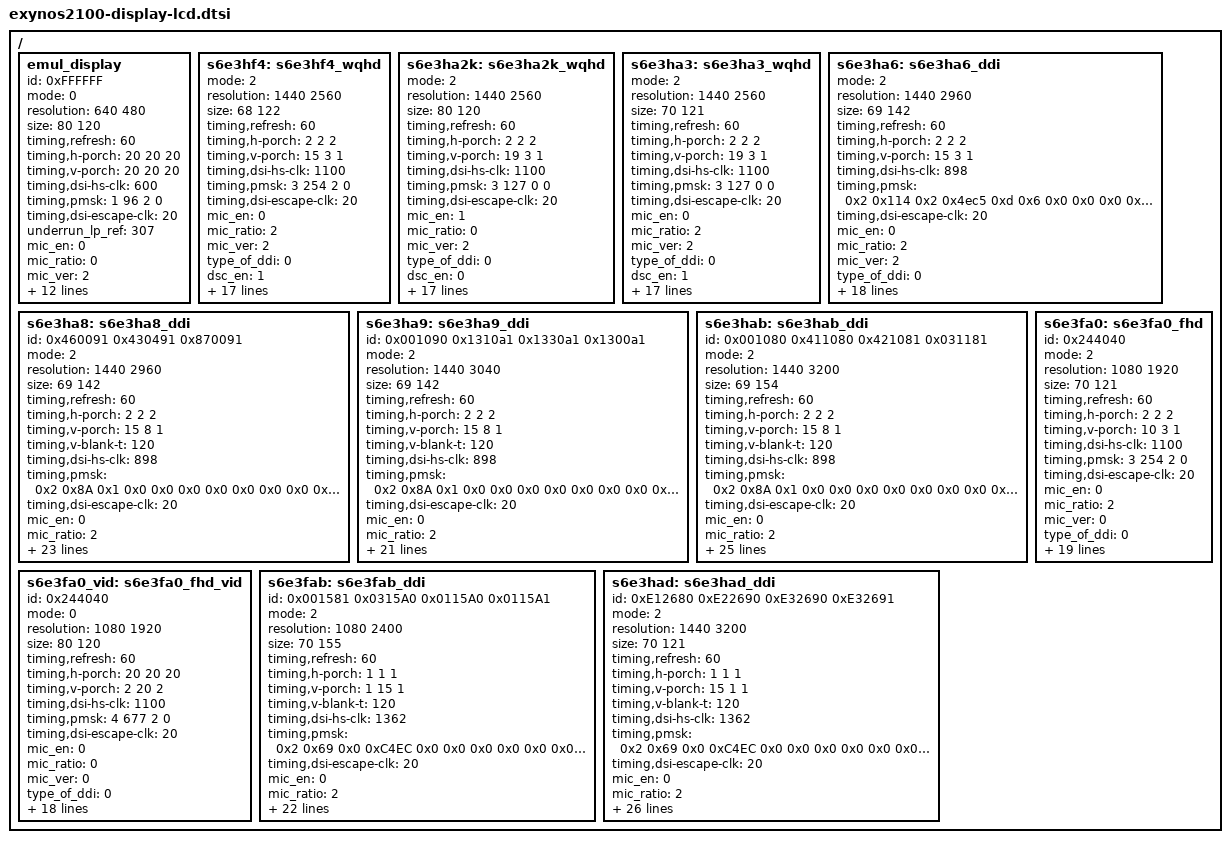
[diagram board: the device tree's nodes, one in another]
/*
 * SAMSUNG LCD Panel Device Tree Source
 *
 * Copyright (c) 2017 Samsung Electronics Co., Ltd.
 *		http://www.samsung.com
 *
 * This program is free software; you can redistribute it and/or modify
 * it under the terms of the GNU General Public License version 2 as
 * published by the Free Software Foundation.
 */

/ {
	fragment@lcd {
		target-path = "/";
		__overlay__ {
			emul_display: emul_display {
				id = <0xFFFFFF>;
				mode = <0>; /* 0: video mode, 1: DP command mode, 2: MIPI command mode */
				resolution = <640 480>;
		/*		resolution = <1080 1920>; */
				size = <80 120>;
				timing,refresh = <60>;
				timing,h-porch = <20 20 20>;
				timing,v-porch = <20 20 20>;
				timing,dsi-hs-clk = <600>;
				/* TODO : pmsk value to be set */
				timing,pmsk = <1 96 2 0>;
				timing,dsi-escape-clk = <20>;
				underrun_lp_ref = <307>;
				mic_en = <0>;			/* 0: Disable, 1: Enable */
				mic_ratio = <0>;		/* 0: 1/2 mic, 1: 1/3 mic */
				mic_ver = <2>;			/* 0: mic v1.1, 1: v1.2, 2: v2.0 */
				type_of_ddi = <0>;		/* 0: Samsung Mobile, 1: MAGNA, 2: Normal(Etc) */
				dsc_en = <0>;			/* 0: Disable, 1: Enable */
				dsc_cnt = <0>;			/* used DSC count */
				dsc_slice_num = <0>;		/* count of dsc slice */
				data_lane = <4>;		/* number of using data lane */
				cmd_underrun_lp_ref = <1203>;	/* for underrun detect at command mode*/
				vt_compensation = <10731>;	/* wclk = 100MHZ, 320 x 240 for underrun detect at video mode*/
				hdr_num = <0>;			/* max: 4 */
				hdr_type = <0 0 0 0>;		/* 1: DOLBY_VISION, 2: HDR10, 3: HLG */
				hdr_max_luma = <0>;		/* 0 */
				hdr_max_avg_luma = <0>;		/* 0 */
				hdr_min_luma = <0>;		/* 0.0000 */
			};

			s6e3hf4: s6e3hf4_wqhd {
				mode = <2>;			/* 0: video mode, 1: DP command mode, 2: MIPI command mode */
				resolution = <1440 2560>; 	/* <720 1280> - dsc disable, <1440 2560> - dsc enable */
				size = <68 122>;
				timing,refresh = <60>;
				timing,h-porch = <2 2 2>;
				timing,v-porch = <15 3 1>;
				timing,dsi-hs-clk = <1100>;	/* <600> - <3 277 3 0>, <898> - <2 138 2 0> */
				timing,pmsk = <3 254 2 0>;
				timing,dsi-escape-clk = <20>;
				mic_en = <0>;			/* 0: Disable, 1: Enable */
				mic_ratio = <2>;		/* 0: 1/2 mic, 1: 1/3 mic */
				mic_ver = <2>;			/* 0: mic v1.1, 1: v1.2, 2: v2.0 */
				type_of_ddi = <0>;		/* 0: Samsung Mobile, 1: MAGNA, 2: Normal(Etc) */
				dsc_en = <1>;			/* 0: Disable, 1: Enable */
				dsc_cnt = <2>;			/* used DSC count */
				dsc_slice_num = <4>;		/* count of dsc slice */
				dsc_slice_h = <64>;		/* height of dsc slice */
				data_lane = <4>;		/* number of using data lane */
				cmd_underrun_lp_ref = <5629>;	/* for underrun detect (max : 65535) */
				mres_en = <0>;
				mres_number = <1>;
				mres_width = <1440 0 0>;
				mres_height = <2560 0 0>;
				mres_dsc_width = <360 0 0>;
				mres_dsc_height = <64 0 0>;
				mres_dsc_en = <1 0 0>;
				hdr_num = <1>;			/* max: 4 */
				hdr_type = <2 0 0 0>;		/* 1: DOLBY_VISION, 2: HDR10, 3: HLG */
				hdr_max_luma = <5400000>;	/* 540 */
				hdr_max_avg_luma = <1200000>;	/* 120 */
				hdr_min_luma = <5>;		/* 0.0005 */
			};

			s6e3ha2k: s6e3ha2k_wqhd {
				mode = <2>;			/* 0: video mode, 1: DP command mode, 2: MIPI command mode */
				resolution = <1440 2560>;
				size = <80 120>;
				timing,refresh = <60>;
				timing,h-porch = <2 2 2>;
				timing,v-porch = <19 3 1>;
				timing,dsi-hs-clk = <1100>;
				timing,pmsk = <3 127 0 0>;
				timing,dsi-escape-clk = <20>;
				mic_en = <1>;			/* 0: Disable, 1: Enable */
				mic_ratio = <0>;		/* 0: 1/2 mic, 1: 1/3 mic */
				mic_ver = <2>;			/* 0: mic v1.1, 1: v1.2, 2: v2.0 */
				type_of_ddi = <0>;		/* 0: Samsung Mobile, 1: MAGNA, 2: Normal(Etc) */
				dsc_en = <0>;			/* 0: Disable, 1: Enable */
				dsc_cnt = <0>;			/* used DSC count */
				dsc_slice_num = <0>;		/* count of dsc slice */
				dsc_slice_h = <0>;		/* height of dsc slice */
				data_lane = <4>;		/* number of using data lane */
				cmd_underrun_lp_ref = <1203>;	/* for underrun detect*/
				mres_en = <0>;
				mres_number = <1>;
				mres_width = <1440 0 0>;
				mres_height = <2560 0 0>;
				mres_dsc_width = <0 0 0>;
				mres_dsc_height = <0 0 0>;
				mres_dsc_en = <0 0 0>;
				hdr_num = <1>;			/* max: 4 */
				hdr_type = <2 0 0 0>;		/* 1: DOLBY_VISION, 2: HDR10, 3: HLG */
				hdr_max_luma = <5400000>;	/* 540 */
				hdr_max_avg_luma = <1200000>;	/* 120 */
				hdr_min_luma = <5>;		/* 0.0005 */
			};

			s6e3ha3: s6e3ha3_wqhd {
				mode = <2>;			/* 0: video mode, 1: DP command mode, 2: MIPI command mode */
				resolution = <1440 2560>;
				size = <70 121>;
				timing,refresh = <60>;
				timing,h-porch = <2 2 2>;
				timing,v-porch = <19 3 1>;
				timing,dsi-hs-clk = <1100>;
				timing,pmsk = <3 127 0 0>;
				timing,dsi-escape-clk = <20>;
				mic_en = <0>;			/* 0: Disable, 1: Enable */
				mic_ratio = <2>;		/* 0: 1/2 mic, 1: 1/3 mic */
				mic_ver = <2>;			/* 0: mic v1.1, 1: v1.2, 2: v2.0 */
				type_of_ddi = <0>;		/* 0: Samsung Mobile, 1: MAGNA, 2: Normal(Etc) */
				dsc_en = <1>;			/* 0: Disable, 1: Enable */
				dsc_cnt = <1>;			/* used DSC count */
				dsc_slice_num = <1>;		/* count of dsc slice */
				dsc_slice_h = <32>;		/* height of dsc slice */
				data_lane = <4>;		/* number of using data lane */
				cmd_underrun_lp_ref = <1203>;	/* for underrun detect*/
				mres_en = <0>;
				mres_number = <1>;
				mres_width = <1440 0 0>;
				mres_height = <2560 0 0>;
				mres_dsc_width = <1440 0 0>;
				mres_dsc_height = <32 0 0>;
				mres_dsc_en = <1 0 0>;
				hdr_num = <1>;			/* max: 4 */
				hdr_type = <2 0 0 0>;		/* 1: DOLBY_VISION, 2: HDR10, 3: HLG */
				hdr_max_luma = <5400000>;	/* 540 */
				hdr_max_avg_luma = <1200000>;	/* 120 */
				hdr_min_luma = <5>;		/* 0.0005 */
			};

			s6e3ha6: s6e3ha6_ddi {
				mode = <2>;
				resolution = <1440 2960>;
				size = <69 142>;
				timing,refresh = <60>;
				timing,h-porch = <2 2 2>;
				timing,v-porch = <15 3 1>;
				timing,dsi-hs-clk = <898>;
				timing,pmsk = <
					0x2 0x114 0x2 0x4ec5 /* p m s k */
					0xd 0x6 0x0 0x0    /* mfr mrr sel_pf icp */
					0x0 0x0 0x0 0x0    /* afc_enb extafc feed_en fsel */
					0x0 0x0              /* fout_mask rsel */
					>;
				timing,dsi-escape-clk = <20>;
				mic_en = <0>;			/* 0: Disable, 1: Enable */
				mic_ratio = <2>;		/* 0: 1/2 mic, 1: 1/3 mic */
				mic_ver = <2>;			/* 0: mic v1.1, 1: v1.2, 2: v2.0 */
				type_of_ddi = <0>;		/* 0: Samsung Mobile, 1: MAGNA, 2: Normal(Etc) */
				dsc_en = <1>;			/* 0: Disable, 1: Enable */
				dsc_cnt = <2>;			/* used DSC count */
				dsc_slice_num = <2>;		/* count of dsc slice */
				dsc_slice_h = <40>;		/* height of dsc slice */
				data_lane = <4>;		/* number of using data lane */
				cmd_underrun_lp_ref = <3744 5359 4367>;	/* for underrun detect*/
				mres_en = <1>;
				mres_number = <3>;
				mres_width = <1440 1080 720>;
				mres_height = <2960 2220 1480>;
				mres_dsc_width = <720 540 360>;
				mres_dsc_height = <40 30 74>;
				mres_dsc_en = <1 1 0>;
				hdr_num = <1>;			/* max: 4 */
				hdr_type = <2 0 0 0>;		/* 1: DOLBY_VISION, 2: HDR10, 3: HLG */
				hdr_max_luma = <5400000>;	/* 540 */
				hdr_max_avg_luma = <1200000>;	/* 120 */
				hdr_min_luma = <5>;		/* 0.0005 */
			};


			s6e3ha8: s6e3ha8_ddi {
				id = <0x460091 0x430491 0x870091>;
				mode = <2>;
				resolution = <1440 2960>;
				size = <69 142>;
				timing,refresh = <60>;
				timing,h-porch = <2 2 2>;
				timing,v-porch = <15 8 1>;
				timing,v-blank-t = <120>;	/* (usec) command: TE pulse time, video: vbp+vfp time */
				timing,dsi-hs-clk = <898>;	/* <600> - <3 277 3 0>, <898> - <2 138 2 0> */
				timing,pmsk = <
					0x2 0x8A  0x1 0x0	/* p m s k */
					0x0 0x0	  0x0 0x0	/* mfr mrr sel_pf icp */
					0x0 0x0   0x0 0x0	/* afc_enb extafc feed_en fsel */
					0x0 0x0          	/* fout_mask rsel */
					>;
				timing,dsi-escape-clk = <20>;
				mic_en = <0>;			/* 0: Disable, 1: Enable */
				mic_ratio = <2>;		/* 0: 1/2 mic, 1: 1/3 mic */
				mic_ver = <2>;			/* 0: mic v1.1, 1: v1.2, 2: v2.0 */
				type_of_ddi = <0>;		/* 0: Samsung Mobile, 1: MAGNA, 2: Normal(Etc) */
				dsc_en = <1>;			/* 0: Disable, 1: Enable */
				dsc_cnt = <2>;			/* used DSC count */
				dsc_slice_num = <2>;		/* count of dsc slice */
				dsc_slice_h = <40>;		/* height of dsc slice */
				data_lane = <4>;		/* number of using data lane */
				mres_en = <1>;
				mres_number = <3>;
				mres_width = <1440 1080 720>;
				mres_height = <2960 2220 1480>;
				mres_dsc_width = <720 540 360>;
				mres_dsc_height = <40 30 74>;
				mres_dsc_en = <1 1 1>;
				default_mode = <0>;
				/* <xres : yres : fps : lp_ref : dsc_en : slice_w : slice_h> */
				display_mode = <1440 2960 60 3022 1 720 40>,
					       <1080 2220 60 5359 1 540 30>,
					       <720 1480 60 7031 1 360 74>;
				hdr_num = <1>;			/* max: 4 */
				hdr_type = <2 0 0 0>;		/* 1: DOLBY_VISION, 2: HDR10, 3: HLG */
				hdr_max_luma = <5400000>;	/* 540 */
				hdr_max_avg_luma = <1200000>;	/* 120 */
				hdr_min_luma = <5>;		/* 0.0005 */
			};

			s6e3ha9: s6e3ha9_ddi {
				id = <0x001090 0x1310a1 0x1330a1 0x1300a1>;
				mode = <2>;
				resolution = <1440 3040>;
				size = <69 142>;
				timing,refresh = <60>;
				timing,h-porch = <2 2 2>;
				timing,v-porch = <15 8 1>;
				timing,v-blank-t = <120>;	/* (usec) command: TE pulse time, video: vbp+vfp time */
				timing,dsi-hs-clk = <898>;	/* <600> - <3 277 3 0>, <898> - <2 138 2 0> */
				timing,pmsk = <
					0x2 0x8A  0x1 0x0    /* p m s k */
					0x0 0x0	  0x0 0x0    /* mfr mrr sel_pf icp */
					0x0 0x0   0x0 0x0    /* afc_enb extafc feed_en fsel */
					0x0 0x0              /* fout_mask rsel */
					>;
				timing,dsi-escape-clk = <20>;
				mic_en = <0>;			/* 0: Disable, 1: Enable */
				mic_ratio = <2>;		/* 0: 1/2 mic, 1: 1/3 mic */
				mic_ver = <2>;			/* 0: mic v1.1, 1: v1.2, 2: v2.0 */
				type_of_ddi = <0>;		/* 0: Samsung Mobile, 1: MAGNA, 2: Normal(Etc) */
				dsc_en = <1>;			/* 0: Disable, 1: Enable */
				dsc_cnt = <2>;			/* used DSC count */
				dsc_slice_num = <2>;		/* count of dsc slice */
				dsc_slice_h = <40>;		/* height of dsc slice */
				data_lane = <4>;		/* number of using data lane */
				mres_en = <0>;
				mres_number = <3>;
				mres_width = <1440 1080 720>;
				mres_height = <3040 2280 1520>;
				mres_dsc_width = <720 540 360>;
				mres_dsc_height = <40 30 74>;
				mres_dsc_en = <1 1 1>;
				default_mode = <0>;
				/* <xres : yres : fps : lp_ref : dsc_en : slice_w : slice_h> */
				display_mode = <1440 3040 60 2877 1 720 40>;
				hdr_num = <1>;			/* max: 4 */
				hdr_type = <2 0 0 0>;		/* 1: DOLBY_VISION, 2: HDR10, 3: HLG */
				hdr_max_luma = <5400000>;	/* 540 */
				hdr_max_avg_luma = <1200000>;	/* 120 */
				hdr_min_luma = <5>;		/* 0.0005 */
			};

			s6e3hab: s6e3hab_ddi {
				id = <0x001080 0x411080 0x421081 0x031181>;
				mode = <2>;
				resolution = <1440 3200>;
				size = <69 154>;
				timing,refresh = <60>;
				timing,h-porch = <2 2 2>;
				timing,v-porch = <15 8 1>;
				timing,v-blank-t = <120>;	/* (usec) command: TE pulse time, video: vbp+vfp time */
				timing,dsi-hs-clk = <898>;	/* <600> - <3 277 3 0>, <898> - <2 138 2 0> */
				timing,pmsk = <
					0x2 0x8A  0x1 0x0	/* p m s k */
					0x0 0x0	  0x0 0x0	/* mfr mrr sel_pf icp */
					0x0 0x0   0x0 0x0	/* afc_enb extafc feed_en fsel */
					0x0 0x0          	/* fout_mask rsel */
					>;
				timing,dsi-escape-clk = <20>;
				mic_en = <0>;			/* 0: Disable, 1: Enable */
				mic_ratio = <2>;		/* 0: 1/2 mic, 1: 1/3 mic */
				mic_ver = <2>;			/* 0: mic v1.1, 1: v1.2, 2: v2.0 */
				type_of_ddi = <0>;		/* 0: Samsung Mobile, 1: MAGNA, 2: Normal(Etc) */
				dsc_en = <1>;			/* 0: Disable, 1: Enable */
				dsc_cnt = <2>;			/* used DSC count */
				dsc_slice_num = <2>;		/* count of dsc slice */
				dsc_slice_h = <40>;		/* height of dsc slice */
				data_lane = <4>;		/* number of using data lane */
				mres_en = <1>;
				mres_number = <3>;
				mres_width = <1440 1080 720>;
				mres_height = <3200 2400 1600>;
				mres_dsc_width = <720 540 360>;
				mres_dsc_height = <40 40 80>;
				mres_dsc_en = <1 1 1>;
				default_mode = <0>;		/* 1440x3200@60fps */
				/* <xres : yres : fps : lp_ref : dsc_en : slice_w : slice_h> */
				display_mode = <1440 3200 60 3022 1 720 40>,
					       <1080 2400 60 5115 1 540 40>,
					       <1080 2400 120 660 1 540 40>,
					       <720 1600 60 6922 1 360 80>,
					       <720 1600 120 2467 1 360 80>;
				hdr_num = <1>;			/* max: 4 */
				hdr_type = <2 0 0 0>;		/* 1: DOLBY_VISION, 2: HDR10, 3: HLG */
				hdr_max_luma = <5400000>;	/* 540 */
				hdr_max_avg_luma = <1200000>;	/* 120 */
				hdr_min_luma = <5>;		/* 0.0005 */
			};

			s6e3fa0: s6e3fa0_fhd {
				id = <0x244040>;
				mode = <2>;             /* 0: video mode, 1: DP command mode, 2: MIPI command mode */
				resolution = <1080 1920>;
				size = <70 121>;
				timing,refresh = <60>;
				timing,h-porch = <2 2 2>;
				timing,v-porch = <10 3 1>;
				timing,dsi-hs-clk = <1100>;
				timing,pmsk = <3 254 2 0>;
				timing,dsi-escape-clk = <20>;
				mic_en = <0>;           /* 0: Disable, 1: Enable */
				mic_ratio = <2>;        /* 0: 1/2 mic, 1: 1/3 mic */
				mic_ver = <0>;          /* 0: mic v1.1, 1: v1.2, 2: v2.0 */
				type_of_ddi = <0>;      /* 0: Samsung Mobile, 1: MAGNA, 2: Normal(Etc) */
				dsc_en = <0>;           /* 0: Disable, 1: Enable */
				dsc_cnt = <0>;          /* used DSC count */
				dsc_slice_num = <0>;    /* count of dsc slice */
				dsc_slice_h = <40>;	/* height of dsc slice */
				data_lane = <4>;	/* number of using data lane */
				mres_en = <0>;
				mres_number = <1>;
				mres_width = <1080 0 0>;
				mres_height = <1920 0 0>;
				mres_dsc_width = <0 0 0>;
				mres_dsc_height = <0 0 0>;
				mres_dsc_en = <0 0 0>;
				default_mode = <0>;
				/* <xres : yres : fps : lp_ref : dsc_en : slice_w : slice_h> */
				display_mode = <1080 1920 60 2467 0 0 0>;
				hdr_num = <1>;		/* max: 4 */
				hdr_type = <2 0 0 0>;	/* 1: DOLBY_VISION, 2: HDR10, 3: HLG */
				hdr_max_luma = <5400000>;		/* 540 */
				hdr_max_avg_luma = <1200000>;	/* 120 */
				hdr_min_luma = <5>;				/* 0.0005 */
			};

			s6e3fa0_vid: s6e3fa0_fhd_vid {
				id = <0x244040>;
				mode = <0>; /* 0: video mode, 1: DP command mode, 2: MIPI command mode */
				resolution = <1080 1920>;
				size = <80 120>;
				timing,refresh = <60>;
				timing,h-porch = <20 20 20>;
				timing,v-porch = <2 20 2>;
				timing,dsi-hs-clk = <1100>;
				/* TODO : pms value to be set */
				timing,pmsk = <4 677 2 0>;
				timing,dsi-escape-clk = <20>;
				mic_en = <0>;		/* 0: Disable, 1: Enable */
				mic_ratio = <0>;	/* 0: 1/2 mic, 1: 1/3 mic */
				mic_ver = <0>;		/* 0: mic v1.1, 1: v1.2, 2: v2.0 */
				type_of_ddi = <0>;	/* 0: Samsung Mobile, 1: MAGNA, 2: Normal(Etc) */
				dsc_en = <0>;		/* 0: Disable, 1: Enable */
				dsc_cnt = <0>;		/* used DSC count */
				dsc_slice_num = <0>;	/* count of dsc slice */
				data_lane = <4>;	/* number of using data lane */
				cmd_underrun_cnt = <4942>;	/* for underrun detect at command mode*/
				vt_compensation = <39>;	/* for underrun detect at video mode*/
				mres_en = <0>;
				mres_number = <3>;
				mres_width = <1440 1080 720>;
				mres_height = <2960 2220 1480>;
				mres_dsc_width = <720 540 360>;
				mres_dsc_height = <40 30 74>;
				mres_dsc_en = <1 1 0>;
				hdr_num = <1>;		/* max: 4 */
				hdr_type = <2 0 0 0>;	/* 1: DOLBY_VISION, 2: HDR10, 3: HLG */
				hdr_max_luma = <5400000>;		/* 540 */
				hdr_max_avg_luma = <1200000>;	/* 120 */
				hdr_min_luma = <5>;				/* 0.0005 */
			};

			s6e3fab: s6e3fab_ddi {
				id = <0x001581 0x0315A0 0x0115A0 0x0115A1>;
				mode = <2>;
				resolution = <1080 2400>;
				size = <70 155>;
				timing,refresh = <60>;
				timing,h-porch = <1 1 1>;
				timing,v-porch = <1 15 1>;
				timing,v-blank-t = <120>;	/* (usec) command: TE pulse time, video: vbp+vfp time */
				timing,dsi-hs-clk = <1362>;	/* <600> - <3 277 3 0>, <898> - <2 138 2 0> */
				timing,pmsk = <
					0x2 0x69  0x0 0xC4EC	/* p m s k */
					0x0 0x0	  0x0 0x0	/* mfr mrr sel_pf icp */
					0x0 0x0   0x0 0x0	/* afc_enb extafc feed_en fsel */
					0x0 0x0          	/* fout_mask rsel */
					>;
				timing,dsi-escape-clk = <20>;
				mic_en = <0>;			/* 0: Disable, 1: Enable */
				mic_ratio = <2>;		/* 0: 1/2 mic, 1: 1/3 mic */
				mic_ver = <2>;			/* 0: mic v1.1, 1: v1.2, 2: v2.0 */
				type_of_ddi = <0>;		/* 0: Samsung Mobile, 1: MAGNA, 2: Normal(Etc) */
				dsc_en = <1>;			/* 0: Disable, 1: Enable */
				dsc_cnt = <2>;			/* used DSC count */
				dsc_slice_num = <2>;		/* count of dsc slice */
				dsc_slice_h = <120>;		/* height of dsc slice */
				data_lane = <4>;		/* number of using data lane */
				mres_en = <1>;
				mres_number = <3>;
				mres_width = <1440 1080 720>;
				mres_height = <3200 2400 1600>;
				mres_dsc_width = <720 540 360>;
				mres_dsc_height = <40 40 80>;
				mres_dsc_en = <1 1 1>;
				default_mode = <0>;		/* 1080x2400@60fps */
				/* <xres : yres : fps : lp_ref : dsc_en : slice_w : slice_h> */
				display_mode = <1080 2400 60 10361 1 540 120>,
					       <1080 2400 120 3337 1 540 120>;
				hdr_num = <1>;			/* max: 4 */
				hdr_type = <2 0 0 0>;		/* 1: DOLBY_VISION, 2: HDR10, 3: HLG */
				hdr_max_luma = <5400000>;	/* 540 */
				hdr_max_avg_luma = <1200000>;	/* 120 */
				hdr_min_luma = <5>;		/* 0.0005 */
			};

			s6e3had: s6e3had_ddi {
				id = <0xE12680 0xE22690 0xE32690 0xE32691>;
				mode = <2>;
				resolution = <1440 3200>;
				size = <70 121>;
				timing,refresh = <60>;
				timing,h-porch = <1 1 1>;
				timing,v-porch = <15 1 1>;
				timing,v-blank-t = <120>;	/* (usec) command: TE pulse time, video: vbp+vfp time */
				timing,dsi-hs-clk = <1362>;
				timing,pmsk = <
					0x2 0x69 0x0 0xC4EC	/* p m s k */
					0x0 0x0  0x0 0x0	/* mfr mrr sel_pf icp */
					0x0 0x0  0x0 0x0	/* afc_enb extafc feed_en fsel */
					0x0 0x0          	/* fout_mask rsel */
					>;
				timing,dsi-escape-clk = <20>;
				mic_en = <0>;			/* 0: Disable, 1: Enable */
				mic_ratio = <2>;		/* 0: 1/2 mic, 1: 1/3 mic */
				mic_ver = <2>;			/* 0: mic v1.1, 1: v1.2, 2: v2.0 */
				type_of_ddi = <0>;		/* 0: Samsung Mobile, 1: MAGNA, 2: Normal(Etc) */
				dsc_en = <1>;			/* 0: Disable, 1: Enable */
				dsc_cnt = <2>;			/* used DSC count */
				dsc_slice_num = <2>;		/* count of dsc slice */
				dsc_slice_h = <40>;		/* height of dsc slice */
				data_lane = <4>;		/* number of using data lane */
				mres_en = <1>;
				mres_number = <3>;
				mres_width = <1440 1080 720>;
				mres_height = <3200 2400 1600>;
				mres_dsc_width = <720 540 360>;
				mres_dsc_height = <40 40 80>;
				mres_dsc_en = <1 1 1>;
				default_mode = <0>;		/* 1440x3200@60fps */
				/* <xres : yres : fps : lp_ref : dsc_en : slice_w : slice_h> */
				display_mode = <1440 3200 60 7834 1 720 40>,
					       <1440 3200 120 810 1 720 40>,
					       <1080 2400 60 10361 1 540 40>,
					       <1080 2400 120 3337 1 540 40>,
					       <720 1600 60 12168 1 360 80>,
					       <720 1600 120 5144 1 360 80>;
				hdr_num = <1>;			/* max: 4 */
				hdr_type = <2 0 0 0>;		/* 1: DOLBY_VISION, 2: HDR10, 3: HLG */
				hdr_max_luma = <5400000>;	/* 540 */
				hdr_max_avg_luma = <1200000>;	/* 120 */
				hdr_min_luma = <5>;		/* 0.0005 */
			};
		};
	};
};
